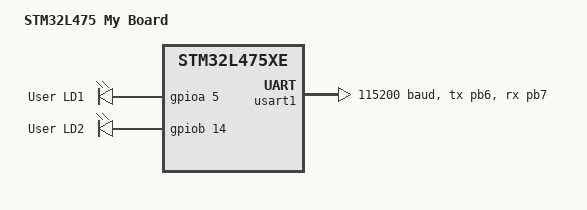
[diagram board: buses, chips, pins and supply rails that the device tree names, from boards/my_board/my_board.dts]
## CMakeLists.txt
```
cmake_minimum_required(VERSION 3.20.0)

list(APPEND BOARD_ROOT ${CMAKE_CURRENT_SOURCE_DIR})
list(APPEND DTS_ROOT ${CMAKE_CURRENT_SOURCE_DIR})
find_package(Zephyr REQUIRED)
project(my_zephyr_app)

target_sources(app PRIVATE src/main.cpp)

add_subdirectory(drivers/my_led_sensor)
```

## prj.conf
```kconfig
CONFIG_GPIO=y
CONFIG_LOG=y
CONFIG_MY_LED_SENSOR=y

#CONFIG_BLINK_SLEEP_250MS=y
#CONFIG_BLINK_SLEEP_TIME_MS=1000
#CONFIG_BLINK_SLEEP_TIME_MS=y    Not allowed as its an integer
```

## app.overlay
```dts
/ {
    aliases{
        app-led = &green_led_2;   // LD1 on STM32L475 Discovery kit
    };

    my_led_sensor0: my_led_sensor {
        compatible = "my-led,sensor";
        status = "okay";
    };
};
```

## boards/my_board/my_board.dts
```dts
/dts-v1/;
#include <st/l4/stm32l475Xe.dtsi>
#include <st/l4/stm32l475v(c-e-g)tx-pinctrl.dtsi>

/ {
	model = "STM32L475 My Board";
	compatible = "bhupendra,my_board";

    aliases {
		led0 = &green_led_1; /* LED GPIO pins from Discovery STM32L475 */
		led1 = &green_led_2; /* LED GPIO pins from Discovery STM32L475 */
    };

    chosen {
		zephyr,console = &usart1;
		zephyr,shell-uart = &usart1;
		zephyr,sram = &sram0;
		zephyr,flash = &flash0;
    };

	leds {
		compatible = "gpio-leds";

		/* LED GPIO pins from Discovery STM32L475 */
		green_led_1: led_1 {
			gpios = <&gpioa 5 GPIO_ACTIVE_HIGH>;
			label = "User LD1";
		};

		/* LED GPIO pins from Discovery STM32L475 */
		green_led_2: led_2 {
			gpios = <&gpiob 14 GPIO_ACTIVE_HIGH>;
			label = "User LD2";
		};
    };
};

&clk_lsi {
	status = "okay";
};

&clk_hsi {
	status = "okay";
};

&pll {
	div-m = <1>;
	mul-n = <20>;
	div-p = <7>;
	div-q = <2>;
	div-r = <4>;
	clocks = <&clk_hsi>;
	status = "okay";
};

&rcc {
	clocks = <&pll>;
	clock-frequency = <DT_FREQ_M(80)>;
	ahb-prescaler = <1>;
	apb1-prescaler = <1>;
	apb2-prescaler = <1>;
};

&usart1 {
	current-speed = <115200>;
	pinctrl-0 = <&usart1_tx_pb6 &usart1_rx_pb7>; // UART pins from Discovery STM32L475 */
	pinctrl-names = "default";
	status = "okay";
};
```

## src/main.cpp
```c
#include <zephyr/drivers/gpio.h>
#include <zephyr/drivers/sensor.h>
#include <zephyr/kernel.h>
#include <zephyr/logging/log.h>
#include "../drivers/my_led_sensor/my_led_sensor.h"

LOG_MODULE_REGISTER(main, LOG_LEVEL_INF);

static const struct device *my_led_sensor = DEVICE_DT_GET(DT_NODELABEL(my_led_sensor0));

int main(void)
{
    if (!device_is_ready(my_led_sensor)) {
        LOG_ERR("our_driver not ready");
        return -ENODEV;
    }

    struct sensor_value value;

    uint32_t loop_count = 0;

    while (1) {
        sensor_sample_fetch(my_led_sensor);
        k_msleep(CONFIG_APP_HEARTBEAT_PERIOD_MS);

        sensor_channel_get(my_led_sensor, SENSOR_CHAN_ALL, &value);
        k_msleep(CONFIG_APP_HEARTBEAT_PERIOD_MS);

        loop_count++;
        if (loop_count % 10 == 0) {
            my_led_sensor_set_blink_count(my_led_sensor, 0);
        }
    }
    return 0;
}
```
